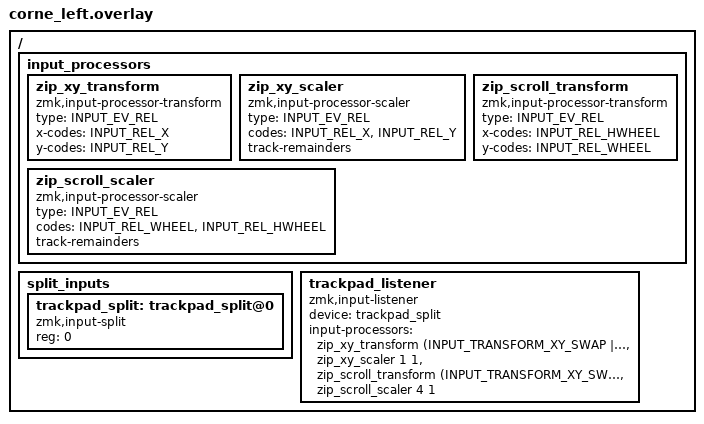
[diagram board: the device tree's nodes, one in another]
#include <dt-bindings/zmk/input_transform.h>
#include <zephyr/dt-bindings/input/input-event-codes.h>

/* Central (Left) half: receives trackpad events from peripheral via input-split */
/ {
    input_processors {
        zip_xy_transform: zip_xy_transform {
            compatible = "zmk,input-processor-transform";
            #input-processor-cells = <1>;
            type = <INPUT_EV_REL>;
            x-codes = <INPUT_REL_X>;
            y-codes = <INPUT_REL_Y>;
        };

        zip_xy_scaler: zip_xy_scaler {
            compatible = "zmk,input-processor-scaler";
            #input-processor-cells = <2>;
            type = <INPUT_EV_REL>;
            codes = <INPUT_REL_X>, <INPUT_REL_Y>;
            track-remainders;
        };

        zip_scroll_transform: zip_scroll_transform {
            compatible = "zmk,input-processor-transform";
            #input-processor-cells = <1>;
            type = <INPUT_EV_REL>;
            x-codes = <INPUT_REL_HWHEEL>;
            y-codes = <INPUT_REL_WHEEL>;
        };

        zip_scroll_scaler: zip_scroll_scaler {
            compatible = "zmk,input-processor-scaler";
            #input-processor-cells = <2>;
            type = <INPUT_EV_REL>;
            codes = <INPUT_REL_WHEEL>, <INPUT_REL_HWHEEL>;
            track-remainders;
        };
    };

    split_inputs {
        #address-cells = <1>;
        #size-cells = <0>;

        trackpad_split: trackpad_split@0 {
            compatible = "zmk,input-split";
            reg = <0>;
        };
    };

    trackpad_listener: trackpad_listener {
        compatible = "zmk,input-listener";
        device = <&trackpad_split>;
        input-processors =
            <&zip_xy_transform (INPUT_TRANSFORM_XY_SWAP | INPUT_TRANSFORM_X_INVERT | INPUT_TRANSFORM_Y_INVERT)>,
            <&zip_xy_scaler 1 1>,
            <&zip_scroll_transform (INPUT_TRANSFORM_XY_SWAP)>,
            <&zip_scroll_scaler 4 1>;
    };
};
